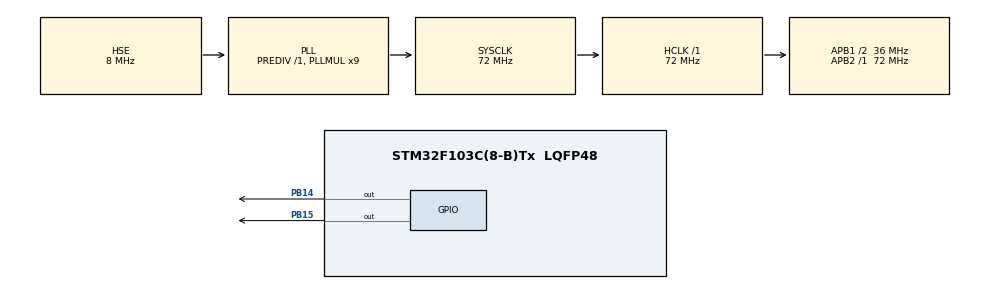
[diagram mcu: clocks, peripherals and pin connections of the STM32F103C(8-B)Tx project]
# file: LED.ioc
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Mcu.Family=STM32F1
Mcu.Name=STM32F103C(8-B)Tx
Mcu.Package=LQFP48
NVIC.PriorityGroup=NVIC_PRIORITYGROUP_4
NVIC.TIM2_IRQn=true\:0\:0\:false\:false\:true\:true\:true\:true
PA13.Mode=Serial_Wire
PA13.Signal=SYS_JTMS-SWDIO
PA14.Mode=Serial_Wire
PA14.Signal=SYS_JTCK-SWCLK
PB14.Signal=GPIO_Output
PB15.Signal=GPIO_Output
PC14-OSC32_IN.Mode=LSE-External-Oscillator
PC14-OSC32_IN.Signal=RCC_OSC32_IN
PC15-OSC32_OUT.Mode=LSE-External-Oscillator
PC15-OSC32_OUT.Signal=RCC_OSC32_OUT
PD0-OSC_IN.Mode=HSE-External-Oscillator
PD0-OSC_IN.Signal=RCC_OSC_IN
PD1-OSC_OUT.Mode=HSE-External-Oscillator
PD1-OSC_OUT.Signal=RCC_OSC_OUT
ProjectManager.HeapSize=0x200
ProjectManager.StackSize=0x400
ProjectManager.TargetToolchain=CMake
RCC.AHBFreq_Value=72000000
RCC.APB1CLKDivider=RCC_HCLK_DIV2
RCC.APB1Freq_Value=36000000
RCC.APB1TimFreq_Value=72000000
RCC.APB2Freq_Value=72000000
RCC.APB2TimFreq_Value=72000000
RCC.HCLKFreq_Value=72000000
RCC.PLLMUL=RCC_PLL_MUL9
RCC.PLLSourceVirtual=RCC_PLLSOURCE_HSE
RCC.SYSCLKFreq_VALUE=72000000
RCC.SYSCLKSource=RCC_SYSCLKSOURCE_PLLCLK
RCC.USBFreq_Value=72000000
TIM2.Period=36000
VP_RTC_VS_RTC_Activate.Mode=RTC_Enabled
VP_TIM2_VS_ClockSourceINT.Mode=Internal
board=custom

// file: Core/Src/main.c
/* USER CODE BEGIN Header */
/**
 ******************************************************************************
 * @file           : main.c
 * @brief          : Main program body
 ******************************************************************************
 * @attention
 *
 * Copyright (c) 2024 STMicroelectronics.
 * All rights reserved.
 *
 * This software is licensed under terms that can be found in the LICENSE file
 * in the root directory of this software component.
 * If no LICENSE file comes with this software, it is provided AS-IS.
 *
 ******************************************************************************
 */
/* USER CODE END Header */
#include "gpio.h"
#include "main.h"
#include "rtc.h"
#include "tim.h"

/* USER CODE BEGIN PV */
uint8_t state = 0;
uint16_t counter = 0;
/* USER CODE END PV */

void SystemClock_Config(void);
void Change_LED_State(void);

int main(void) {

  /* MCU Configuration--------------------------------------------------------*/

  /* Reset of all peripherals, Initializes the Flash interface and the Systick.
   */
  HAL_Init();

  /* Configure the system clock */
  SystemClock_Config();

  /* Initialize all configured peripherals */
  MX_GPIO_Init();
  MX_RTC_Init();
  MX_TIM2_Init();
  /* USER CODE BEGIN 2 */
  HAL_TIM_Base_Start_IT(&htim2);
  /* USER CODE END 2 */

  /* Infinite loop */
  while (1) {
  }
}

void SystemClock_Config(void) {
  RCC_OscInitTypeDef RCC_OscInitStruct = {0};
  RCC_ClkInitTypeDef RCC_ClkInitStruct = {0};
  RCC_PeriphCLKInitTypeDef PeriphClkInit = {0};

  /** Initializes the RCC Oscillators according to the specified parameters
   * in the RCC_OscInitTypeDef structure.
   */
  RCC_OscInitStruct.OscillatorType =
      RCC_OSCILLATORTYPE_LSI | RCC_OSCILLATORTYPE_HSE;
  RCC_OscInitStruct.HSEState = RCC_HSE_ON;
  RCC_OscInitStruct.HSEPredivValue = RCC_HSE_PREDIV_DIV1;
  RCC_OscInitStruct.HSIState = RCC_HSI_ON;
  RCC_OscInitStruct.LSIState = RCC_LSI_ON;
  RCC_OscInitStruct.PLL.PLLState = RCC_PLL_ON;
  RCC_OscInitStruct.PLL.PLLSource = RCC_PLLSOURCE_HSE;
  RCC_OscInitStruct.PLL.PLLMUL = RCC_PLL_MUL9;
  if (HAL_RCC_OscConfig(&RCC_OscInitStruct) != HAL_OK) {
    Error_Handler();
  }

  /** Initializes the CPU, AHB and APB buses clocks
   */
  RCC_ClkInitStruct.ClockType = RCC_CLOCKTYPE_HCLK | RCC_CLOCKTYPE_SYSCLK |
                                RCC_CLOCKTYPE_PCLK1 | RCC_CLOCKTYPE_PCLK2;
  RCC_ClkInitStruct.SYSCLKSource = RCC_SYSCLKSOURCE_PLLCLK;
  RCC_ClkInitStruct.AHBCLKDivider = RCC_SYSCLK_DIV1;
  RCC_ClkInitStruct.APB1CLKDivider = RCC_HCLK_DIV2;
  RCC_ClkInitStruct.APB2CLKDivider = RCC_HCLK_DIV1;

  if (HAL_RCC_ClockConfig(&RCC_ClkInitStruct, FLASH_LATENCY_2) != HAL_OK) {
    Error_Handler();
  }
  PeriphClkInit.PeriphClockSelection = RCC_PERIPHCLK_RTC;
  PeriphClkInit.RTCClockSelection = RCC_RTCCLKSOURCE_LSI;
  if (HAL_RCCEx_PeriphCLKConfig(&PeriphClkInit) != HAL_OK) {
    Error_Handler();
  }
}

/* USER CODE BEGIN 4 */
// will be triggered at a frequency of 2khz
void HAL_TIM_PeriodElapsedCallback(TIM_HandleTypeDef *htim) {
  if (htim->Instance == TIM2) // 判断触发溢出中断的定时器
  {
    counter++;
    if (counter == 2000) {
      Change_LED_State();
      counter = 0;
    }
  }
}

void Change_LED_State(void) { HAL_GPIO_TogglePin(GPIOB, GPIO_PIN_14); }
/* USER CODE END 4 */

void Error_Handler(void) {
  __disable_irq();
  while (1) {
  }
}

#ifdef USE_FULL_ASSERT
/**
 * @brief  Reports the name of the source file and the source line number
 *         where the assert_param error has occurred.
 * @param  file: pointer to the source file name
 * @param  line: assert_param error line source number
 * @retval None
 */
void assert_failed(uint8_t *file, uint32_t line) {
  /* USER CODE BEGIN 6 */
  /* User can add his own implementation to report the file name and line
     number, ex: printf("Wrong parameters value: file %s on line %d\r\n", file,
     line) */
  /* USER CODE END 6 */
}
#endif /* USE_FULL_ASSERT */
